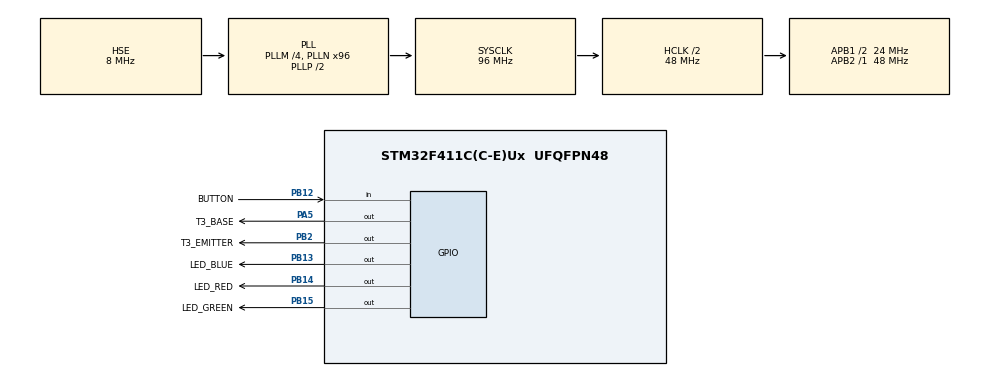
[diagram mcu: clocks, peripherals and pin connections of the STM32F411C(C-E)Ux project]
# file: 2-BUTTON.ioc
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Mcu.Family=STM32F4
Mcu.Name=STM32F411C(C-E)Ux
Mcu.Package=UFQFPN48
NVIC.PriorityGroup=NVIC_PRIORITYGROUP_4
PA5.GPIO_Label=T3_BASE
PA5.Signal=GPIO_Output
PB12.GPIO_Label=BUTTON
PB12.Signal=GPIO_Input
PB13.GPIO_Label=LED_BLUE
PB13.Signal=GPIO_Output
PB14.GPIO_Label=LED_RED
PB14.Signal=GPIO_Output
PB15.GPIO_Label=LED_GREEN
PB15.Signal=GPIO_Output
PB2.GPIO_Label=T3_EMITTER
PB2.Signal=GPIO_Output
PC14-OSC32_IN.Mode=LSE-External-Oscillator
PC14-OSC32_IN.Signal=RCC_OSC32_IN
PC15-OSC32_OUT.Mode=LSE-External-Oscillator
PC15-OSC32_OUT.Signal=RCC_OSC32_OUT
PH0\ -\ OSC_IN.Mode=HSE-External-Oscillator
PH0\ -\ OSC_IN.Signal=RCC_OSC_IN
PH1\ -\ OSC_OUT.Mode=HSE-External-Oscillator
PH1\ -\ OSC_OUT.Signal=RCC_OSC_OUT
ProjectManager.HeapSize=0x400
ProjectManager.StackSize=0x200
ProjectManager.TargetToolchain=SW4STM32
RCC.48MHZClocksFreq_Value=48000000
RCC.AHBCLKDivider=RCC_SYSCLK_DIV2
RCC.AHBFreq_Value=48000000
RCC.APB1CLKDivider=RCC_HCLK_DIV2
RCC.APB1Freq_Value=24000000
RCC.APB1TimCLKDivider=1
RCC.APB1TimFreq_Value=24000000
RCC.APB2Freq_Value=48000000
RCC.APB2TimFreq_Value=48000000
RCC.CortexFreq_Value=48000000
RCC.HCLKFreq_Value=48000000
RCC.HSE_VALUE=8000000
RCC.HSI_VALUE=16000000
RCC.PLLM=4
RCC.PLLN=96
RCC.PLLSourceVirtual=RCC_PLLSOURCE_HSE
RCC.SYSCLKFreq_VALUE=96000000
RCC.SYSCLKSource=RCC_SYSCLKSOURCE_PLLCLK
RCC.VCOOutputFreq_Value=192000000
board=2-BUTTON

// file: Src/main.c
/**
 ******************************************************************************
 * File Name          : main.c
 * Description        : Main program body
 ******************************************************************************
 *
 * COPYRIGHT(c) 2016 STMicroelectronics
 *
 * Redistribution and use in source and binary forms, with or without modification,
 * are permitted provided that the following conditions are met:
 *   1. Redistributions of source code must retain the above copyright notice,
 *      this list of conditions and the following disclaimer.
 *   2. Redistributions in binary form must reproduce the above copyright notice,
 *      this list of conditions and the following disclaimer in the documentation
 *      and/or other materials provided with the distribution.
 *   3. Neither the name of STMicroelectronics nor the names of its contributors
 *      may be used to endorse or promote products derived from this software
 *      without specific prior written permission.
 *
 * THIS SOFTWARE IS PROVIDED BY THE COPYRIGHT HOLDERS AND CONTRIBUTORS "AS IS"
 * AND ANY EXPRESS OR IMPLIED WARRANTIES, INCLUDING, BUT NOT LIMITED TO, THE
 * IMPLIED WARRANTIES OF MERCHANTABILITY AND FITNESS FOR A PARTICULAR PURPOSE ARE
 * DISCLAIMED. IN NO EVENT SHALL THE COPYRIGHT HOLDER OR CONTRIBUTORS BE LIABLE
 * FOR ANY DIRECT, INDIRECT, INCIDENTAL, SPECIAL, EXEMPLARY, OR CONSEQUENTIAL
 * DAMAGES (INCLUDING, BUT NOT LIMITED TO, PROCUREMENT OF SUBSTITUTE GOODS OR
 * SERVICES; LOSS OF USE, DATA, OR PROFITS; OR BUSINESS INTERRUPTION) HOWEVER
 * CAUSED AND ON ANY THEORY OF LIABILITY, WHETHER IN CONTRACT, STRICT LIABILITY,
 * OR TORT (INCLUDING NEGLIGENCE OR OTHERWISE) ARISING IN ANY WAY OUT OF THE USE
 * OF THIS SOFTWARE, EVEN IF ADVISED OF THE POSSIBILITY OF SUCH DAMAGE.
 *
 ******************************************************************************
 */
#include "stm32f4xx_hal.h"

/* USER CODE BEGIN PV */
/* Private variables ---------------------------------------------------------*/

/* USER CODE END PV */

void SystemClock_Config(void);
static void MX_GPIO_Init(void);

/* USER CODE BEGIN PFP */
/* Private function prototypes -----------------------------------------------*/

/* USER CODE END PFP */

int main(void) {

	/* MCU Configuration----------------------------------------------------------*/

	/* Reset of all peripherals, Initializes the Flash interface and the Systick. */
	HAL_Init();

	/* Configure the system clock */
	SystemClock_Config();

	/* Initialize all configured peripherals */
	MX_GPIO_Init();

	/* USER CODE BEGIN 2 */
	HAL_GPIO_WritePin(LED_RED_GPIO_Port, LED_RED_Pin, 1);
	HAL_GPIO_WritePin(LED_GREEN_GPIO_Port, LED_GREEN_Pin, 1);
	HAL_GPIO_WritePin(LED_BLUE_GPIO_Port, LED_BLUE_Pin, 1);
	/* USER CODE END 2 */

	/* Infinite loop */
	while (1) {

		/* USER CODE BEGIN 3 */
		if (HAL_GPIO_ReadPin(BUTTON_GPIO_Port, BUTTON_Pin)) {
			HAL_GPIO_WritePin(LED_RED_GPIO_Port, LED_RED_Pin, 0);
			HAL_GPIO_WritePin(LED_BLUE_GPIO_Port, LED_BLUE_Pin, 1);
		} else {
			HAL_GPIO_WritePin(LED_RED_GPIO_Port, LED_RED_Pin, 1);
			HAL_GPIO_WritePin(LED_BLUE_GPIO_Port, LED_BLUE_Pin, 0);
		}
	}
	/* USER CODE END 3 */

}

/** System Clock Configuration
 */
void SystemClock_Config(void) {

	RCC_OscInitTypeDef RCC_OscInitStruct;
	RCC_ClkInitTypeDef RCC_ClkInitStruct;

	__PWR_CLK_ENABLE()
	;

	__HAL_PWR_VOLTAGESCALING_CONFIG(PWR_REGULATOR_VOLTAGE_SCALE1);

	RCC_OscInitStruct.OscillatorType = RCC_OSCILLATORTYPE_HSE;
	RCC_OscInitStruct.HSEState = RCC_HSE_ON;
	RCC_OscInitStruct.PLL.PLLState = RCC_PLL_ON;
	RCC_OscInitStruct.PLL.PLLSource = RCC_PLLSOURCE_HSE;
	RCC_OscInitStruct.PLL.PLLM = 4;
	RCC_OscInitStruct.PLL.PLLN = 96;
	RCC_OscInitStruct.PLL.PLLP = RCC_PLLP_DIV2;
	RCC_OscInitStruct.PLL.PLLQ = 4;
	HAL_RCC_OscConfig(&RCC_OscInitStruct);

	RCC_ClkInitStruct.ClockType = RCC_CLOCKTYPE_HCLK | RCC_CLOCKTYPE_SYSCLK
			| RCC_CLOCKTYPE_PCLK1 | RCC_CLOCKTYPE_PCLK2;
	RCC_ClkInitStruct.SYSCLKSource = RCC_SYSCLKSOURCE_PLLCLK;
	RCC_ClkInitStruct.AHBCLKDivider = RCC_SYSCLK_DIV2;
	RCC_ClkInitStruct.APB1CLKDivider = RCC_HCLK_DIV2;
	RCC_ClkInitStruct.APB2CLKDivider = RCC_HCLK_DIV1;
	HAL_RCC_ClockConfig(&RCC_ClkInitStruct, FLASH_LATENCY_1);

	HAL_SYSTICK_Config(HAL_RCC_GetHCLKFreq() / 1000);

	HAL_SYSTICK_CLKSourceConfig(SYSTICK_CLKSOURCE_HCLK);

	/* SysTick_IRQn interrupt configuration */
	HAL_NVIC_SetPriority(SysTick_IRQn, 0, 0);
}

/** Configure pins as
 * Analog
 * Input
 * Output
 * EVENT_OUT
 * EXTI
 */
void MX_GPIO_Init(void) {

	GPIO_InitTypeDef GPIO_InitStruct;

	/* GPIO Ports Clock Enable */
	__GPIOC_CLK_ENABLE()
	;
	__GPIOH_CLK_ENABLE()
	;
	__GPIOA_CLK_ENABLE()
	;
	__GPIOB_CLK_ENABLE()
	;

	/*Configure GPIO pin Output Level */
	HAL_GPIO_WritePin(T3_BASE_GPIO_Port, T3_BASE_Pin, GPIO_PIN_RESET);

	/*Configure GPIO pin Output Level */
	HAL_GPIO_WritePin(GPIOB,
	T3_EMITTER_Pin | LED_BLUE_Pin | LED_RED_Pin | LED_GREEN_Pin,
			GPIO_PIN_RESET);

	/*Configure GPIO pin : T3_BASE_Pin */
	GPIO_InitStruct.Pin = T3_BASE_Pin;
	GPIO_InitStruct.Mode = GPIO_MODE_OUTPUT_PP;
	GPIO_InitStruct.Pull = GPIO_NOPULL;
	GPIO_InitStruct.Speed = GPIO_SPEED_LOW;
	HAL_GPIO_Init(T3_BASE_GPIO_Port, &GPIO_InitStruct);

	/*Configure GPIO pins : T3_EMITTER_Pin LED_BLUE_Pin LED_RED_Pin LED_GREEN_Pin */
	GPIO_InitStruct.Pin = T3_EMITTER_Pin | LED_BLUE_Pin | LED_RED_Pin
			| LED_GREEN_Pin;
	GPIO_InitStruct.Mode = GPIO_MODE_OUTPUT_PP;
	GPIO_InitStruct.Pull = GPIO_NOPULL;
	GPIO_InitStruct.Speed = GPIO_SPEED_LOW;
	HAL_GPIO_Init(GPIOB, &GPIO_InitStruct);

	/*Configure GPIO pin : BUTTON_Pin */
	GPIO_InitStruct.Pin = BUTTON_Pin;
	GPIO_InitStruct.Mode = GPIO_MODE_INPUT;
	GPIO_InitStruct.Pull = GPIO_NOPULL;
	HAL_GPIO_Init(BUTTON_GPIO_Port, &GPIO_InitStruct);

}

/************************ (C) COPYRIGHT STMicroelectronics *****END OF FILE****/
